VERSION ""

NS_ :

BS_:

BU_: Host Device

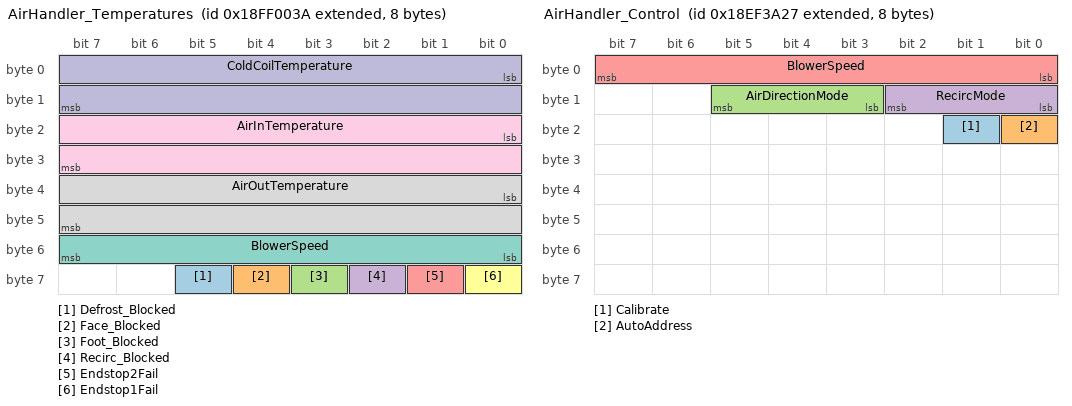
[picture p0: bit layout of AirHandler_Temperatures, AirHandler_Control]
BO_ 2566848570 AirHandler_Temperatures: 8 Device
 SG_ Defrost_Blocked : 61|1@1+ (1,0) [0|1] ""  Host
 SG_ Face_Blocked : 60|1@1+ (1,0) [0|1] ""  Host
 SG_ Foot_Blocked : 59|1@1+ (1,0) [0|1] ""  Host
 SG_ Recirc_Blocked : 58|1@1+ (1,0) [0|1] ""  Host
 SG_ Endstop2Fail : 57|1@1+ (1,0) [0|1] ""  Host
 SG_ Endstop1Fail : 56|1@1+ (1,0) [0|1] ""  Host
 SG_ BlowerSpeed : 48|8@1+ (0.4,0) [0|102] "%"  Host
 SG_ AirOutTemperature : 32|16@1+ (0.03125,-273) [-273|1774.97] "C"  Host
 SG_ AirInTemperature : 16|16@1+ (0.03125,-273) [-273|1774.97] "C"  Host
 SG_ ColdCoilTemperature : 0|16@1+ (0.03125,-273) [-273|1774.97] "C"  Host

BO_ 2566848826 AirHandler_Status1: 8 Device
 SG_ Defrost_Act_Position : 56|8@1+ (10,0) [0|2550] "steps"  Host
 SG_ Defrost_Act_Stall : 55|1@1+ (1,0) [0|1] ""  Host
 SG_ Defrost_Act_Voltage : 53|2@1+ (1,0) [0|3] ""  Host
 SG_ Defrost_Act_Temp : 52|1@1+ (1,0) [0|1] ""  Host
 SG_ Defrost_Act_Response : 51|1@1+ (1,0) [0|1] ""  Host
 SG_ Addressing_Status : 48|3@1+ (1,0) [0|7] ""  Host
 SG_ Face_Act_Position : 40|8@1+ (10,0) [0|2550] "steps"  Host
 SG_ Face_Act_Stall : 39|1@1+ (1,0) [0|1] ""  Host
 SG_ Face_Act_Voltage : 37|2@1+ (1,0) [0|3] ""  Host
 SG_ Face_Act_Temp : 36|1@1+ (1,0) [0|1] ""  Host
 SG_ Face_Act_Response : 35|1@1+ (1,0) [0|1] ""  Host
 SG_ Calibration_Status : 32|3@1+ (1,0) [0|7] ""  Host
 SG_ Foot_Act_Position : 24|8@1+ (10,0) [0|2550] "steps"  Host
 SG_ Foot_Act_Stall : 23|1@1+ (1,0) [0|1] ""  Host
 SG_ Foot_Act_Voltage : 21|2@1+ (1,0) [0|3] ""  Host
 SG_ Foot_Act_Temp : 20|1@1+ (1,0) [0|1] ""  Host
 SG_ Foot_Act_Response : 19|1@1+ (1,0) [0|1] ""  Host
 SG_ AirDirectionMode : 16|3@1+ (1,0) [0|7] ""  Host
 SG_ RecircActPosition : 8|8@1+ (10,0) [0|2550] "steps"  Host
 SG_ RecircActStall : 7|1@1+ (1,0) [0|1] ""  Host
 SG_ RecircActVoltage : 5|2@1+ (1,0) [0|3] ""  Host
 SG_ RecircActTemp : 4|1@1+ (1,0) [0|1] ""  Host
 SG_ RecircActResponse : 3|1@1+ (1,0) [0|1] ""  Host
 SG_ RecircMode : 0|3@1+ (1,0) [0|7] ""  Host

BO_ 2565814823 AirHandler_Control: 8 Host
 SG_ Calibrate : 17|1@1+ (1,0) [0|1] ""  Device
 SG_ AutoAddress : 16|1@1+ (1,0) [0|1] ""  Device
 SG_ AirDirectionMode : 11|3@1+ (1,0) [0|7] ""  Device
 SG_ RecircMode : 8|3@1+ (1,0) [0|7] ""  Device
 SG_ BlowerSpeed : 0|8@1+ (0.4,0) [0|102] "%"  Device

BO_ 2566863399 AirHandler_RecircOVR: 2 Host
 SG_ Recirc_Override_Position : 8|8@1+ (1,0) [0|100] "%"  Device
 SG_ Recirc_Override_Enable : 0|1@1+ (1,0) [0|1] ""  Device

CM_ "$File: //depot/auto/dbc/Third_party_components/Bergstorm/HVAC_ECU/0.3.1.0/HVAC_ECU.dbc $
$Change: 215801 $
$DateTime: 2024/08/14 11:32:08 $
$Revision: #1 $";
BA_DEF_  "DBName" STRING ;
BA_DEF_ BO_  "GenMsgSendType" ENUM  "cyclic","NotUsed","NotUsed","NotUsed","NotUsed","NotUsed","NotUsed","IfActive","noMsgSendType";
BA_DEF_ SG_  "GenSignalSendType" ENUM  "Cyclic","OnWrite","OnWriteWithRepetition","OnChange","OnChangeWithRepetition","IfActive","IfActiveWithRepetition";
BA_DEF_ BO_  "GenMsgCycleTime" INT 0 1000;
BA_DEF_DEF_  "GenMsgSendType" "noMsgSendType";
BA_DEF_DEF_  "GenSignalSendType" "OnChange";
BA_DEF_DEF_  "GenMsgCycleTime" 0;
BA_DEF_DEF_  "DBName" "HVAC_ECU";
BA_ "GenMsgSendType" BO_ 2566848570 0;
BA_ "GenMsgCycleTime" BO_ 2566848570 1000;
BA_ "GenMsgSendType" BO_ 2566848826 0;
BA_ "GenMsgCycleTime" BO_ 2566848826 1000;
BA_ "GenMsgSendType" BO_ 2565814823 0;
BA_ "GenMsgCycleTime" BO_ 2565814823 100;
BA_ "GenSignalSendType" SG_ 2566848826 Addressing_Status 0;
VAL_ 2566848570 Endstop2Fail 1 "Fail" 0 "Good" ;
VAL_ 2566848570 Endstop1Fail 1 "Fail" 0 "Good" ;
VAL_ 2566848826 Defrost_Act_Stall 1 "Stalled" 0 "Normal" ;
VAL_ 2566848826 Defrost_Act_Voltage 2 "UnderVoltage" 1 "OverVoltage" 0 "Normal" ;
VAL_ 2566848826 Defrost_Act_Temp 1 "OverHeated" 0 "Normal" ;
VAL_ 2566848826 Defrost_Act_Response 1 "Error" 0 "Normal" ;
VAL_ 2566848826 Addressing_Status 1 "Addressing" 0 "Not Addressing" ;
VAL_ 2566848826 Face_Act_Stall 1 "Stalled" 0 "Normal" ;
VAL_ 2566848826 Face_Act_Voltage 2 "UnderVoltage" 1 "OverVoltage" 0 "Normal" ;
VAL_ 2566848826 Face_Act_Temp 1 "OverHeated" 0 "Normal" ;
VAL_ 2566848826 Face_Act_Response 1 "Error" 0 "Normal" ;
VAL_ 2566848826 Calibration_Status 1 "Calibrating" 0 "Not Calibrating" ;
VAL_ 2566848826 Foot_Act_Stall 1 "Stalled" 0 "Normal" ;
VAL_ 2566848826 Foot_Act_Voltage 2 "UnderVoltage" 1 "OverVoltage" 0 "Normal" ;
VAL_ 2566848826 Foot_Act_Temp 1 "OverHeated" 0 "Normal" ;
VAL_ 2566848826 Foot_Act_Response 1 "Error" 0 "Normal" ;
VAL_ 2566848826 AirDirectionMode 4 "Screen" 3 "Floor/Screen" 2 "Floor" 1 "Face/Floor" 0 "Face" ;
VAL_ 2566848826 RecircActStall 1 "Stalled" 0 "Normal" ;
VAL_ 2566848826 RecircActVoltage 2 "UnderVoltage" 1 "OverVoltage" 0 "Normal" ;
VAL_ 2566848826 RecircActTemp 1 "OverHeated" 0 "Normal" ;
VAL_ 2566848826 RecircActResponse 1 "Error" 0 "Normal" ;
VAL_ 2566848826 RecircMode 0 "Recirc" 1 "Fresh" ;
VAL_ 2565814823 AirDirectionMode 4 "Screen" 3 "Floor/Screen" 2 "Floor" 1 "Face/Floor" 0 "Face" ;
VAL_ 2565814823 RecircMode 0 "Recirc" 1 "Fresh" ;
VAL_ 2566863399 Recirc_Override_Enable 1 "Enabled" 0 "Disabled" ;
